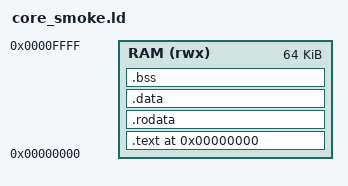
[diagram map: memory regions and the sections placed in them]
OUTPUT_ARCH(riscv)
ENTRY(_start)
MEMORY { RAM (rwx) : ORIGIN = 0x00000000, LENGTH = 64K }
SECTIONS {
    . = ORIGIN(RAM);
    .text : { KEEP(*(.text.start)) *(.text*) } > RAM
    .rodata : { *(.rodata*) } > RAM
    .data : { *(.data*) } > RAM
    .bss : {
        . = ALIGN(4);
        __bss_start = .;
        *(.bss*) *(COMMON)
        . = ALIGN(4);
        __bss_end = .;
    } > RAM
    . = ALIGN(16);
    _stack_top = ORIGIN(RAM) + LENGTH(RAM);
    ASSERT(. < _stack_top, "program exceeds SRAM")
}
